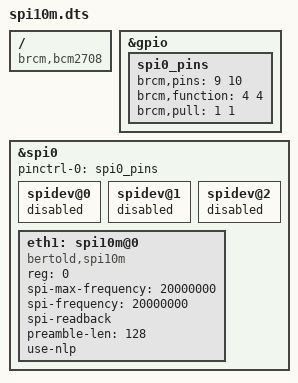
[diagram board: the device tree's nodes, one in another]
/dts-v1/;
/plugin/;

/ {
	compatible = "brcm,bcm2708";

	fragment@0 {
		target = <&gpio>;
		__overlay__ {
			/* 
			 * We only enable MOSI as output and MISO as input (for readback).
			 * Enable pulldown on both pins to get a stable value during packets.
			 * It seems the SPI peripheral tri-states MOSI when not doing a
			 * transaction.
			 */
			spi0_pins: spi0_pins {
				brcm,pins = <9 10>;
				brcm,function = <4 4>;
				brcm,pull = <1 1>;
			};
		};
	};

	fragment@1 {
		target = <&spi0>;
		__overlay__ {
			/* Needed to avoid dtc warning */
			#address-cells = <1>;
			#size-cells = <0>;

			status = "okay";
			
			pinctrl-names = "default";
			pinctrl-0 = <&spi0_pins>;

			spidev@0{
				status = "disabled";
			};
			
			spidev@1{
				status = "disabled";
			};
			
			spidev@2{
				status = "disabled";
			};

			eth1: spi10m@0{
				compatible = "bertold,spi10m";
				reg = <0>;
				spi-max-frequency = <20000000>;
				spi-frequency = <20000000>;
				spi-readback;
				preamble-len = <128>;
				use-nlp;
				status = "okay";
			};
		};
	};
};
